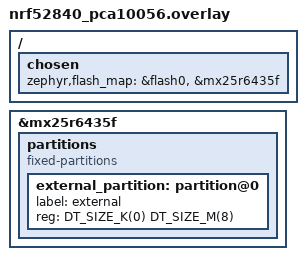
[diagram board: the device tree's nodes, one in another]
/ {
 	chosen {
		zephyr,flash_map = &flash0, &mx25r6435f;
	};
};

&mx25r6435f {
	partitions {
		compatible = "fixed-partitions";
		#address-cells = <1>;
		#size-cells = <1>;

 		external_partition: partition@0 {
			label = "external";
			reg = <DT_SIZE_K(0) DT_SIZE_M(8)>;
		};
	};
};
